# demosoc register map
Vendor: Nuclei; Series: Nuclei Evaluation Demo SoC
Nuclei Evaluation Demo SoC using Nuclei N/NX Core
CPU: Demosoc, little endian
Registers are 8-bit, read-write, reset 0x0 unless marked. A register's access mark holds for its fields unless they carry their own. Offsets are from the block's base; lines under a group give offsets from that group; [hi:lo] are bit positions; {n}, {i} and the like mark numbered series; 'fields as' and 'values as' point back to an identical list; <NAME> marks a mode.

## Memory map
0x02000000 MTIMER size 0x10000 — System Timer.
0x0C000000 ECLIC size 0xFFFF — Enhanced Core Local Interrupt Controller
0x10012000 GPIO0 size 0x1000 — General purpose input/output controller.
0x10013000 UART0 size 0x1000 — Universal Asynchronous Receiver/Transmitter.
0x10014000 QSPI0 size 0x1000 — Serial Peripheral Interface.
0x10015000 PWM0 size 0x1000 — Pulse-Width Modulation.
0x10023000 UART1 size 0x1000 — Universal Asynchronous Receiver/Transmitter.
0x10024000 QSPI1 size 0x1000 — Serial Peripheral Interface.
0x10025000 PWM1 size 0x1000
0x10034000 QSPI2 size 0x1000 — Serial Peripheral Interface.
0x10035000 PWM2 size 0x1000

## Interrupts
3 UART0_IRQ (UART0)
4 UART1_IRQ (UART1)
5 QSPI0_IRQ (QSPI0)
6 QSPI1_IRQ (QSPI1)
7 QSPI2_IRQ (QSPI2)
{n+8} GPIO_{n}_IRQ (GPIO0) (n=0..12)
21 GPIO_12_IRQ (GPIO0)
22 GPIO_14_IRQ (GPIO0)
23 GPIO_14_IRQ (GPIO0)
{n+8} GPIO_{n}_IRQ (GPIO0) (n=16..28)
37 GPIO_28_IRQ (GPIO0)
38 GPIO_30_IRQ (GPIO0)
39 GPIO_31_IRQ (GPIO0)
40 PWMO_CMP0_IRQ (PWM0)
41 PWMO_CMP1_IRQ (PWM0)
42 PWMO_CMP2_IRQ (PWM0)
43 PWMO_CMP3_IRQ (PWM0)
44 PWM1_CMP0_IRQ (PWM1)
45 PWM1_CMP1_IRQ (PWM1)
46 PWM1_CMP2_IRQ (PWM1)
47 PWM1_CMP3_IRQ (PWM1)
48 PWM2_CMP0_IRQ (PWM2)
49 PWM2_CMP1_IRQ (PWM2)
50 PWM2_CMP2_IRQ (PWM2)
51 PWM2_CMP3_IRQ (PWM2)

## ECLIC — Enhanced Core Local Interrupt Controller
Base 0x0C000000
0x00 CLICCFG
  [4:1] NLBITS
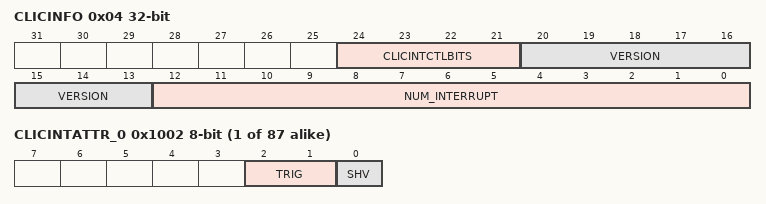
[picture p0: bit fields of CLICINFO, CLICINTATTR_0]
0x04 CLICINFO 32-bit ro
  [24:21] CLICINTCTLBITS, [20:13] VERSION, [12:0] NUM_INTERRUPT
0x0B MTH
{0x1000+4i} CLICINTIP_{i} (i=0..84) — clicintip Register
  [0] IP
{0x1001+4i} CLICINTIE_{i} (i=0..86) — clicintie Register
  [0] IE
{0x1002+4i} CLICINTATTR_{i} (i=0..86) — clicintattr Register
  [2:1] TRIG, [0] SHV
{0x1003+4i} CLICINTCTL_{i} (i=0..86) — clicintctl Register
  [7:0] LEVEL_PRIORITY
0x1158 CLICINTIP_85 — clicintip Register
  [0] IP
0x115C CLICINTIP_86 — clicintip Register
  [0] IP

## MTIMER — System Timer.
Base 0x02000000
0x00 MTIME_LO 32-bit — Machine Timer Register Low.
0x04 MTIME_HI 32-bit — Machine Timer Register High.
0x08 MTIMECMP_LO 32-bit — Machine Timer Compare Register Low.
0x0C MTIMECMP_HI 32-bit — Machine Timer Compare Register High.
0xFF0 MSFTRST 32-bit — Machine Timer Software Core Reset Register.
0xFF8 MIMECTL 32-bit — Machine Timer Control Register.
0xFFC MSIP 32-bit — Machine Software Interrupt Pending Register.

## GPIO0 — General purpose input/output controller.
Base 0x10012000
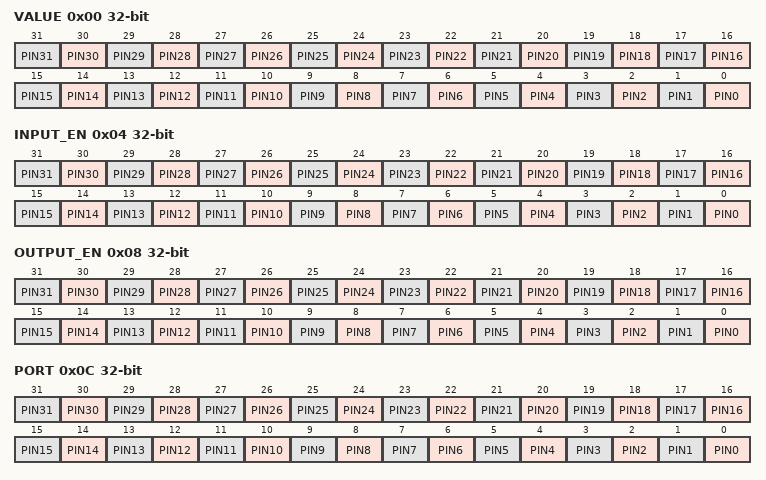
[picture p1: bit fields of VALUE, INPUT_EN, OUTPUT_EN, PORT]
0x00 VALUE 32-bit — Pin value.
  [n] PIN{n} (n=0..31)
0x04 INPUT_EN 32-bit — Pin input enable.
  [n] PIN{n} (n=0..31)
0x08 OUTPUT_EN 32-bit — Pin output enable.
  [n] PIN{n} (n=0..31)
0x0C PORT 32-bit — Output port value.
  [n] PIN{n} (n=0..31)
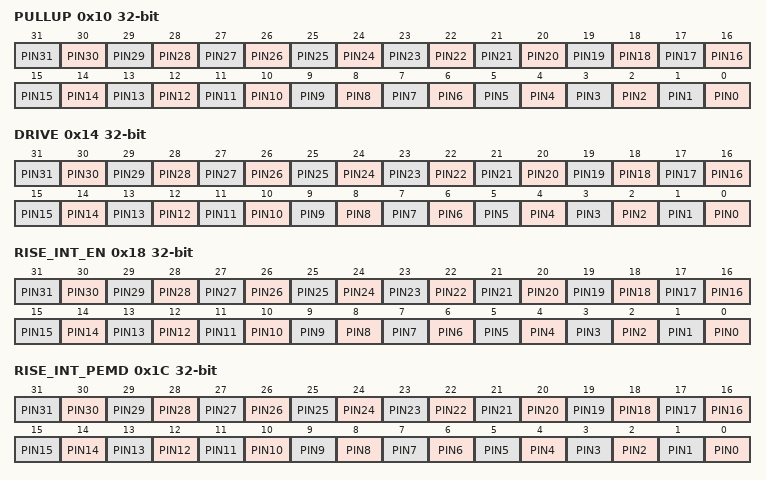
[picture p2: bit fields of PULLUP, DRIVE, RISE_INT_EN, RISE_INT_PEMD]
0x10 PULLUP 32-bit — Internal Pull-Up enable.
  [n] PIN{n} (n=0..31)
0x14 DRIVE 32-bit — Drive Strength.
  [n] PIN{n} (n=0..31)
0x18 RISE_INT_EN 32-bit — Rise interrupt enable.
  [n] PIN{n} (n=0..31)
0x1C RISE_INT_PEMD 32-bit — Rise interrupt pending.
  [n] PIN{n} (n=0..31)
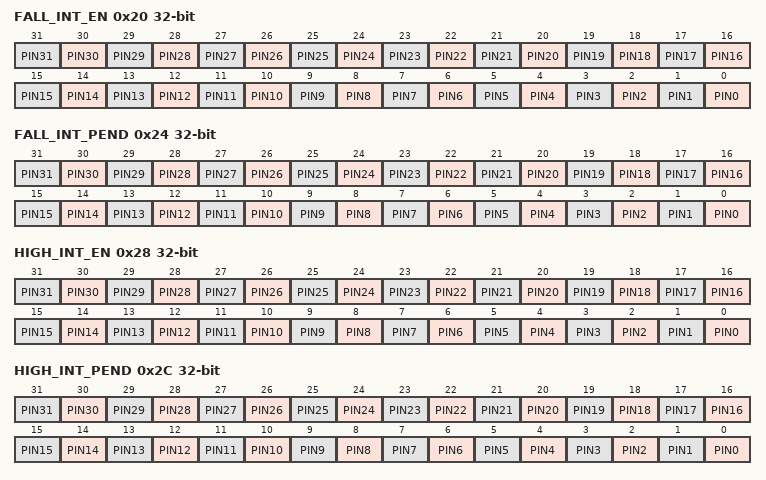
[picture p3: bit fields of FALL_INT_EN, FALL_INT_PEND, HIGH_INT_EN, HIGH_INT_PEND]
0x20 FALL_INT_EN 32-bit — Fall interrupt enable.
  [n] PIN{n} (n=0..31)
0x24 FALL_INT_PEND 32-bit — Fall interrupt pending.
  [n] PIN{n} (n=0..31)
0x28 HIGH_INT_EN 32-bit — High interrupt enable.
  [n] PIN{n} (n=0..31)
0x2C HIGH_INT_PEND 32-bit — High interrupt pending.
  [n] PIN{n} (n=0..31)
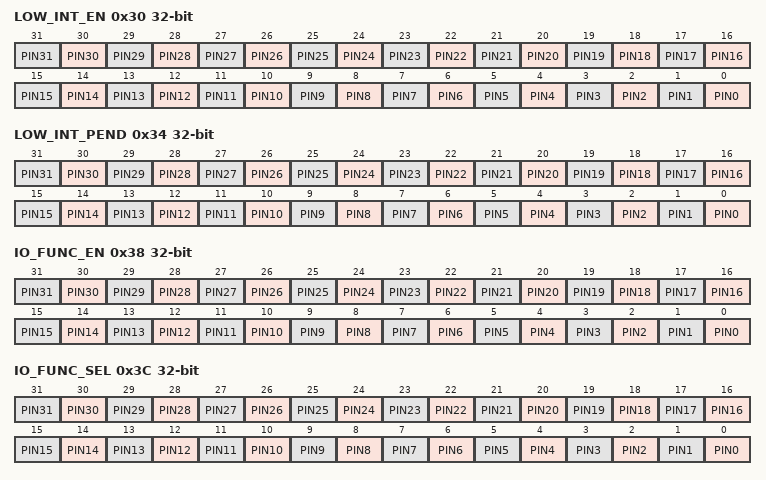
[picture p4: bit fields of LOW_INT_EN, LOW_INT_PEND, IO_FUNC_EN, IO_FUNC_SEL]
0x30 LOW_INT_EN 32-bit — Low interrupt enable.
  [n] PIN{n} (n=0..31)
0x34 LOW_INT_PEND 32-bit — Low interrupt pending.
  [n] PIN{n} (n=0..31)
0x38 IO_FUNC_EN 32-bit — HW I/O function enable.
  [n] PIN{n} (n=0..31)
0x3C IO_FUNC_SEL 32-bit — HW I/O function select.
  [n] PIN{n} (n=0..31)
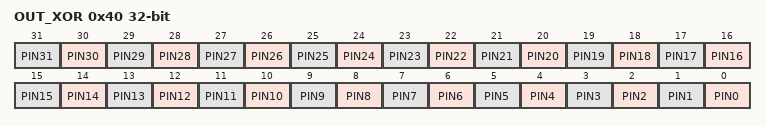
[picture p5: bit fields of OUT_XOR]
0x40 OUT_XOR 32-bit — Output XOR (invert).
  [n] PIN{n} (n=0..31)

## QSPI0 — Serial Peripheral Interface.
Base 0x10014000
Same registers: QSPI1 0x10024000, QSPI2 0x10034000
0x00 SCKDIV 32-bit — Serial Clock Divisor Register.
  [11:0] SCALE
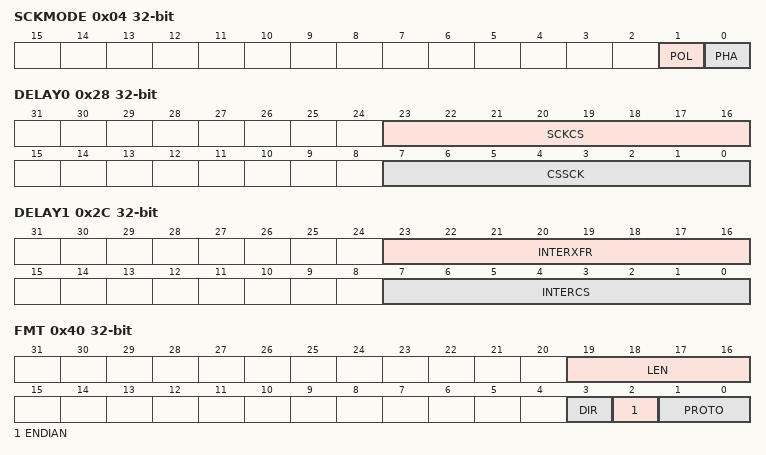
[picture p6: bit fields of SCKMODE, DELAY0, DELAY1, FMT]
0x04 SCKMODE 32-bit — Serial Clock Mode Register.
  [1] POL — Serial Clock Polarity
    0=Inactive state of SCK is logical 0; 1=Inactive state of SCK is logical 1
  [0] PHA — Serial Clock Phase
    0=Data is sampled on the leading edge of SCK and shifted on the trailing edge of SCK; 1=Data is shifted on the leading edge of SCK and sampled on the trailing edge of SCK
0x10 CSID 32-bit — Chip Select ID Register.
0x14 CSDEF 32-bit — Chip Select Default Register.
0x18 CSMODE 32-bit — Chip Select Mode Register.
  [1:0] MODE
    0=AUTO (Assert/de-assert CS at the beginning/end of each frame.); 2=HOLD (Keep CS continuously asserted after the initial frame.); 3=OFF (Disable hardware control of the CS pin.)
0x28 DELAY0 32-bit — Delay Control Register 0.
  [23:16] SCKCS, [7:0] CSSCK
0x2C DELAY1 32-bit — Delay Control Register 1.
  [23:16] INTERXFR, [7:0] INTERCS
0x40 FMT 32-bit — Frame Format Register.
  [19:16] LEN
  [3] DIR
    0=RX (For dual and quad protocols, the DQ pins are tri-stated. For the single protocol, the DQ0 pin is driven with the transmit data as normal.); 1=TX (The receive FIFO is not populated.)
  [2] ENDIAN
    0=MSB_First (Tansmit most-significant bit first.); 1=LSB_First (Transmit least-significant bit first.)
  [1:0] PROTO
    0=Single (Data Pins: DQ0 (MOSI), DQ1 (MISO).); 1=Dual (Data Pins: DQ0, DQ1.); 2=Quad (Data Pins: DQ0, DQ1, DQ2, DQ3.)
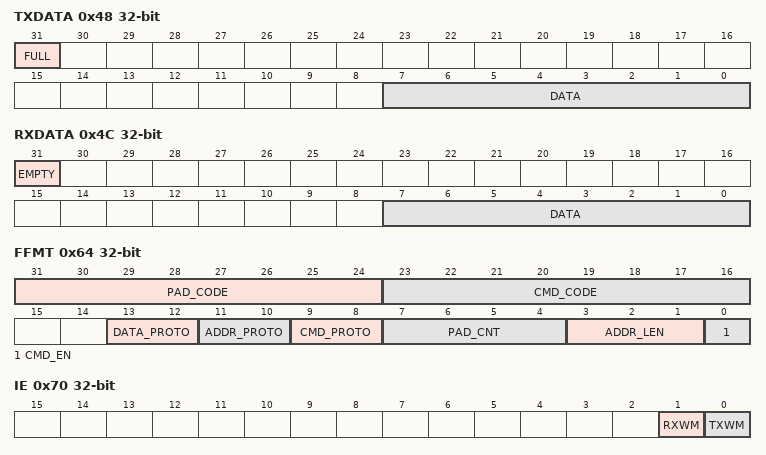
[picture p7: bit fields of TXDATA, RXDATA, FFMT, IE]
0x48 TXDATA 32-bit — Transmit Data Register.
  [31] FULL, [7:0] DATA
0x4C RXDATA 32-bit — Receive Data Register.
  [31] EMPTY, [7:0] DATA
0x50 TXMARK 32-bit — Transmit Watermark Register.
  [2:0] TXMARK
0x54 RXMARK 32-bit — Receive Watermark Register.
  [2:0] RXMARK
0x60 FCTRL 32-bit — SPI Flash Interface Control Register.
  [0] ENABLE
0x64 FFMT 32-bit — SPI Flash Instruction Format Register.
  [31:24] PAD_CODE, [23:16] CMD_CODE, [13:12] DATA_PROTO, [11:10] ADDR_PROTO, [9:8] CMD_PROTO, [7:4] PAD_CNT, [3:1] ADDR_LEN, [0] CMD_EN
0x70 IE 32-bit — SPI Interrupt Enable Register.
  [1] RXWM, [0] TXWM
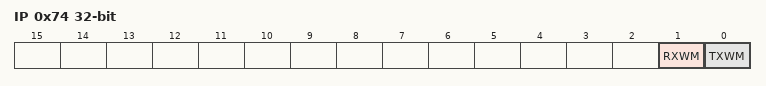
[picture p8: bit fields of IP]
0x74 IP 32-bit — SPI Interrupt Pending Register.
  [1] RXWM, [0] TXWM

## UART0 — Universal Asynchronous Receiver/Transmitter.
Base 0x10013000
Same registers: UART1 0x10023000
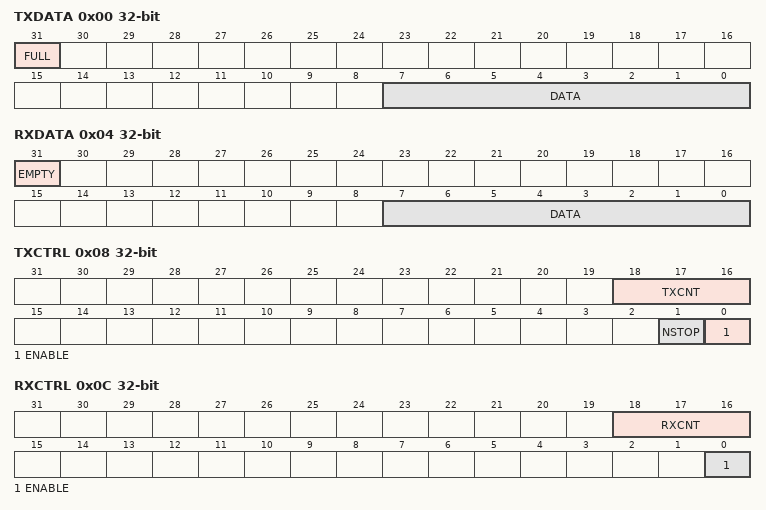
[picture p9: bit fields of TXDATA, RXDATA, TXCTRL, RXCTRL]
0x00 TXDATA 32-bit — Transmit Data Register.
  [31] FULL, [7:0] DATA
0x04 RXDATA 32-bit — Receive Data Register.
  [31] EMPTY, [7:0] DATA
0x08 TXCTRL 32-bit — Transmit Control Register.
  [18:16] TXCNT, [1] NSTOP, [0] ENABLE
0x0C RXCTRL 32-bit — Receive Control Register.
  [18:16] RXCNT, [0] ENABLE
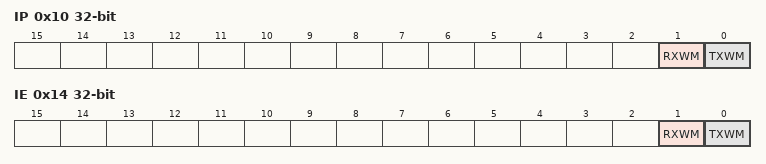
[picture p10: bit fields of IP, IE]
0x10 IP 32-bit — Interrupt Pending Register.
  [1] RXWM, [0] TXWM
0x14 IE 32-bit — Interrupt Enable Register.
  [1] RXWM, [0] TXWM
0x18 DIV 32-bit — Baud Rate Divisor Register (BAUD = Fin / (DIV + 1)).
  [15:0] DIV

## PWM0 — Pulse-Width Modulation.
Base 0x10015000
Same registers: PWM1 0x10025000, PWM2 0x10035000
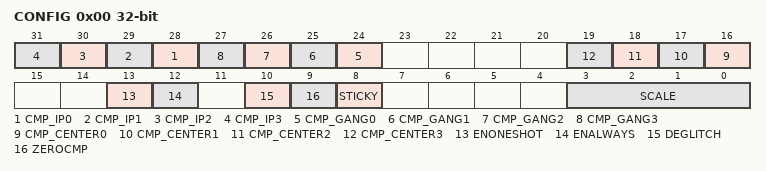
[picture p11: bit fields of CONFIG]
0x00 CONFIG 32-bit — PWM Configuration Register.
  [n+28] CMP_IP{n} (n=0..3), [n+24] CMP_GANG{n} (n=0..3), [n+16] CMP_CENTER{n} (n=0..3), [13] ENONESHOT, [12] ENALWAYS, [10] DEGLITCH, [9] ZEROCMP, [8] STICKY, [3:0] SCALE
0x08 COUNT 32-bit — PWM Count Register.
  [30:0] CNT
0x10 SCALE_COUNT 32-bit — PWM Scaled Counter Register.
  [15:0] CNT
{0x20+4i} COMPARE{i} 32-bit (i=0..3) — PWM Compare Register.
  [15:0] COMPARE
